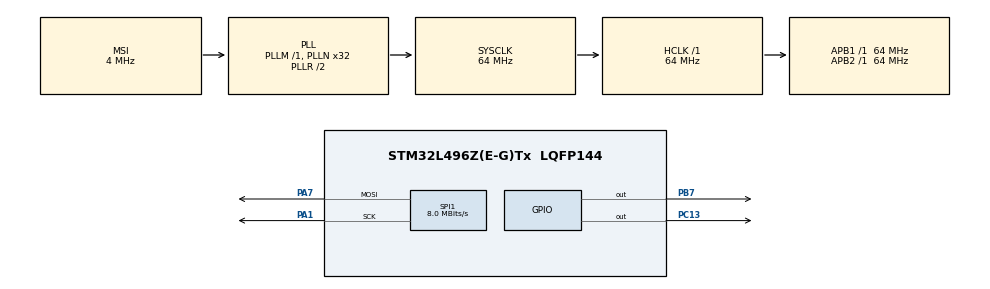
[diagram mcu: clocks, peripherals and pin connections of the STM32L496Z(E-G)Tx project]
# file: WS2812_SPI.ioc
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Dma.Request0=SPI1_TX
Dma.SPI1_TX.0.Direction=DMA_MEMORY_TO_PERIPH
Dma.SPI1_TX.0.Instance=DMA1_Channel3
Dma.SPI1_TX.0.MemDataAlignment=DMA_MDATAALIGN_BYTE
Dma.SPI1_TX.0.MemInc=DMA_MINC_ENABLE
Dma.SPI1_TX.0.Mode=DMA_NORMAL
Dma.SPI1_TX.0.PeriphDataAlignment=DMA_PDATAALIGN_BYTE
Dma.SPI1_TX.0.PeriphInc=DMA_PINC_DISABLE
Dma.SPI1_TX.0.Priority=DMA_PRIORITY_LOW
Mcu.Family=STM32L4
Mcu.Name=STM32L496Z(E-G)Tx
Mcu.Package=LQFP144
NVIC.DMA1_Channel3_IRQn=true\:0\:0\:false\:false\:true\:false
NVIC.PriorityGroup=NVIC_PRIORITYGROUP_4
PA1.Mode=TX_Only_Simplex_Unidirect_Master
PA1.Signal=SPI1_SCK
PA7.Mode=TX_Only_Simplex_Unidirect_Master
PA7.Signal=SPI1_MOSI
PB7.GPIO_PuPd=GPIO_PULLUP
PB7.GPIO_Speed=GPIO_SPEED_FREQ_HIGH
PB7.Signal=GPIO_Output
PC13.GPIO_PuPd=GPIO_PULLUP
PC13.Signal=GPIO_Output
ProjectManager.HeapSize=0x200
ProjectManager.StackSize=0x400
ProjectManager.TargetToolchain=MDK-ARM V5
RCC.AHBFreq_Value=64000000
RCC.APB1Freq_Value=64000000
RCC.APB1TimFreq_Value=64000000
RCC.APB2Freq_Value=64000000
RCC.APB2TimFreq_Value=64000000
RCC.CortexFreq_Value=64000000
RCC.HCLKFreq_Value=64000000
RCC.HSE_VALUE=8000000
RCC.HSI48_VALUE=48000000
RCC.HSI_VALUE=16000000
RCC.LSE_VALUE=32768
RCC.MSI_VALUE=4000000
RCC.PLLN=32
RCC.SYSCLKFreq_VALUE=64000000
RCC.SYSCLKSource=RCC_SYSCLKSOURCE_PLLCLK
RCC.VCOOutputFreq_Value=128000000
SPI1.BaudRatePrescaler=SPI_BAUDRATEPRESCALER_8
SPI1.CalculateBaudRate=8.0 MBits/s
SPI1.DataSize=SPI_DATASIZE_8BIT
SPI1.Direction=SPI_DIRECTION_2LINES
SPI1.Mode=SPI_MODE_MASTER
SPI1.VirtualType=VM_MASTER
board=WS2812_SPI

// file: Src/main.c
/**
  ******************************************************************************
  * @file           : main.c
  * @brief          : Main program body
  ******************************************************************************
  ** This notice applies to any and all portions of this file
  * that are not between comment pairs USER CODE BEGIN and
  * USER CODE END. Other portions of this file, whether
  * inserted by the user or by software development tools
  * are owned by their respective copyright owners.
  *
  * COPYRIGHT(c) 2018 STMicroelectronics
  *
  * Redistribution and use in source and binary forms, with or without modification,
  * are permitted provided that the following conditions are met:
  *   1. Redistributions of source code must retain the above copyright notice,
  *      this list of conditions and the following disclaimer.
  *   2. Redistributions in binary form must reproduce the above copyright notice,
  *      this list of conditions and the following disclaimer in the documentation
  *      and/or other materials provided with the distribution.
  *   3. Neither the name of STMicroelectronics nor the names of its contributors
  *      may be used to endorse or promote products derived from this software
  *      without specific prior written permission.
  *
  * THIS SOFTWARE IS PROVIDED BY THE COPYRIGHT HOLDERS AND CONTRIBUTORS "AS IS"
  * AND ANY EXPRESS OR IMPLIED WARRANTIES, INCLUDING, BUT NOT LIMITED TO, THE
  * IMPLIED WARRANTIES OF MERCHANTABILITY AND FITNESS FOR A PARTICULAR PURPOSE ARE
  * DISCLAIMED. IN NO EVENT SHALL THE COPYRIGHT HOLDER OR CONTRIBUTORS BE LIABLE
  * FOR ANY DIRECT, INDIRECT, INCIDENTAL, SPECIAL, EXEMPLARY, OR CONSEQUENTIAL
  * DAMAGES (INCLUDING, BUT NOT LIMITED TO, PROCUREMENT OF SUBSTITUTE GOODS OR
  * SERVICES; LOSS OF USE, DATA, OR PROFITS; OR BUSINESS INTERRUPTION) HOWEVER
  * CAUSED AND ON ANY THEORY OF LIABILITY, WHETHER IN CONTRACT, STRICT LIABILITY,
  * OR TORT (INCLUDING NEGLIGENCE OR OTHERWISE) ARISING IN ANY WAY OUT OF THE USE
  * OF THIS SOFTWARE, EVEN IF ADVISED OF THE POSSIBILITY OF SUCH DAMAGE.
  *
  ******************************************************************************
  */
#include "main.h"
#include "stm32l4xx_hal.h"

/* USER CODE BEGIN Includes */
#include "Adafruit_NeoPixel.h"
#include "stdbool.h"
#include "L3G4200D.h"
/* USER CODE END Includes */

SPI_HandleTypeDef hspi1;
DMA_HandleTypeDef hdma_spi1_tx;

/* USER CODE BEGIN PV */
/* Private variables ---------------------------------------------------------*/
static GPIO_InitTypeDef  GPIO_InitStruct;

/* USER CODE END PV */

void SystemClock_Config(void);
static void MX_GPIO_Init(void);
static void MX_DMA_Init(void);
static void MX_SPI1_Init(void);

/* USER CODE BEGIN PFP */
/* Private function prototypes -----------------------------------------------*/

/* USER CODE END PFP */

int main(void)
{

	/* MCU Configuration----------------------------------------------------------*/

	/* Reset of all peripherals, Initializes the Flash interface and the Systick. */
	HAL_Init();

	/* Configure the system clock */
	SystemClock_Config();

	/* Initialize all configured peripherals */
	MX_GPIO_Init();
	MX_DMA_Init();
	MX_SPI1_Init();
	/* USER CODE BEGIN 2 */

	WS2812B_Init();
	WS2812B_Test();

	Init_L3G4200D();
	/* USER CODE END 2 */

	/* Infinite loop */
	/* USER CODE BEGIN WHILE */
	while (1)
	{
		READ_L3G4200D();
		HAL_Delay(20);
		/* USER CODE END WHILE */

	}

}

void SystemClock_Config(void)
{

  RCC_OscInitTypeDef RCC_OscInitStruct;
  RCC_ClkInitTypeDef RCC_ClkInitStruct;

    /**Initializes the CPU, AHB and APB busses clocks
    */
  RCC_OscInitStruct.OscillatorType = RCC_OSCILLATORTYPE_MSI;
  RCC_OscInitStruct.MSIState = RCC_MSI_ON;
  RCC_OscInitStruct.MSICalibrationValue = 0;
  RCC_OscInitStruct.MSIClockRange = RCC_MSIRANGE_6;
  RCC_OscInitStruct.PLL.PLLState = RCC_PLL_ON;
  RCC_OscInitStruct.PLL.PLLSource = RCC_PLLSOURCE_MSI;
  RCC_OscInitStruct.PLL.PLLM = 1;
  RCC_OscInitStruct.PLL.PLLN = 32;
  RCC_OscInitStruct.PLL.PLLP = RCC_PLLP_DIV2;
  RCC_OscInitStruct.PLL.PLLQ = RCC_PLLQ_DIV2;
  RCC_OscInitStruct.PLL.PLLR = RCC_PLLR_DIV2;
  if (HAL_RCC_OscConfig(&RCC_OscInitStruct) != HAL_OK)
  {
    _Error_Handler(__FILE__, __LINE__);
  }

    /**Initializes the CPU, AHB and APB busses clocks
    */
  RCC_ClkInitStruct.ClockType = RCC_CLOCKTYPE_HCLK|RCC_CLOCKTYPE_SYSCLK
                              |RCC_CLOCKTYPE_PCLK1|RCC_CLOCKTYPE_PCLK2;
  RCC_ClkInitStruct.SYSCLKSource = RCC_SYSCLKSOURCE_PLLCLK;
  RCC_ClkInitStruct.AHBCLKDivider = RCC_SYSCLK_DIV1;
  RCC_ClkInitStruct.APB1CLKDivider = RCC_HCLK_DIV1;
  RCC_ClkInitStruct.APB2CLKDivider = RCC_HCLK_DIV1;

  if (HAL_RCC_ClockConfig(&RCC_ClkInitStruct, FLASH_LATENCY_3) != HAL_OK)
  {
    _Error_Handler(__FILE__, __LINE__);
  }

    /**Configure the main internal regulator output voltage
    */
  if (HAL_PWREx_ControlVoltageScaling(PWR_REGULATOR_VOLTAGE_SCALE1) != HAL_OK)
  {
    _Error_Handler(__FILE__, __LINE__);
  }

    /**Configure the Systick interrupt time
    */
  HAL_SYSTICK_Config(HAL_RCC_GetHCLKFreq()/1000);

    /**Configure the Systick
    */
  HAL_SYSTICK_CLKSourceConfig(SYSTICK_CLKSOURCE_HCLK);

  /* SysTick_IRQn interrupt configuration */
  HAL_NVIC_SetPriority(SysTick_IRQn, 0, 0);
}

/* SPI1 init function */
static void MX_SPI1_Init(void)
{

  /* SPI1 parameter configuration*/
  hspi1.Instance = SPI1;
  hspi1.Init.Mode = SPI_MODE_MASTER;
  hspi1.Init.Direction = SPI_DIRECTION_2LINES;
  hspi1.Init.DataSize = SPI_DATASIZE_8BIT;
  hspi1.Init.CLKPolarity = SPI_POLARITY_LOW;
  hspi1.Init.CLKPhase = SPI_PHASE_1EDGE;
  hspi1.Init.NSS = SPI_NSS_SOFT;
  hspi1.Init.BaudRatePrescaler = SPI_BAUDRATEPRESCALER_8;
  hspi1.Init.FirstBit = SPI_FIRSTBIT_MSB;
  hspi1.Init.TIMode = SPI_TIMODE_DISABLE;
  hspi1.Init.CRCCalculation = SPI_CRCCALCULATION_DISABLE;
  hspi1.Init.CRCPolynomial = 7;
  hspi1.Init.CRCLength = SPI_CRC_LENGTH_DATASIZE;
  hspi1.Init.NSSPMode = SPI_NSS_PULSE_ENABLE;
  if (HAL_SPI_Init(&hspi1) != HAL_OK)
  {
    _Error_Handler(__FILE__, __LINE__);
  }

}

static void MX_DMA_Init(void)
{
  /* DMA controller clock enable */
  __HAL_RCC_DMA1_CLK_ENABLE();

  /* DMA interrupt init */
  /* DMA1_Channel3_IRQn interrupt configuration */
  HAL_NVIC_SetPriority(DMA1_Channel3_IRQn, 0, 0);
  HAL_NVIC_EnableIRQ(DMA1_Channel3_IRQn);

}

/** Configure pins as
        * Analog
        * Input
        * Output
        * EVENT_OUT
        * EXTI
*/
static void MX_GPIO_Init(void)
{

  GPIO_InitTypeDef GPIO_InitStruct;

  /* GPIO Ports Clock Enable */
  __HAL_RCC_GPIOC_CLK_ENABLE();
  __HAL_RCC_GPIOA_CLK_ENABLE();
  __HAL_RCC_GPIOB_CLK_ENABLE();

  /*Configure GPIO pin Output Level */
  HAL_GPIO_WritePin(GPIOC, GPIO_PIN_13, GPIO_PIN_RESET);

  /*Configure GPIO pin Output Level */
  HAL_GPIO_WritePin(GPIOB, GPIO_PIN_7, GPIO_PIN_RESET);

  /*Configure GPIO pin : PC13 */
  GPIO_InitStruct.Pin = GPIO_PIN_13;
  GPIO_InitStruct.Mode = GPIO_MODE_OUTPUT_PP;
  GPIO_InitStruct.Pull = GPIO_PULLUP;
  GPIO_InitStruct.Speed = GPIO_SPEED_FREQ_LOW;
  HAL_GPIO_Init(GPIOC, &GPIO_InitStruct);

  /*Configure GPIO pin : PB7 */
  GPIO_InitStruct.Pin = GPIO_PIN_7;
  GPIO_InitStruct.Mode = GPIO_MODE_OUTPUT_PP;
  GPIO_InitStruct.Pull = GPIO_PULLUP;
  GPIO_InitStruct.Speed = GPIO_SPEED_FREQ_HIGH;
  HAL_GPIO_Init(GPIOB, &GPIO_InitStruct);

}

void _Error_Handler(char *file, int line)
{
	while(1)
	{
	}
}

/************************ (C) COPYRIGHT STMicroelectronics *****END OF FILE****/
